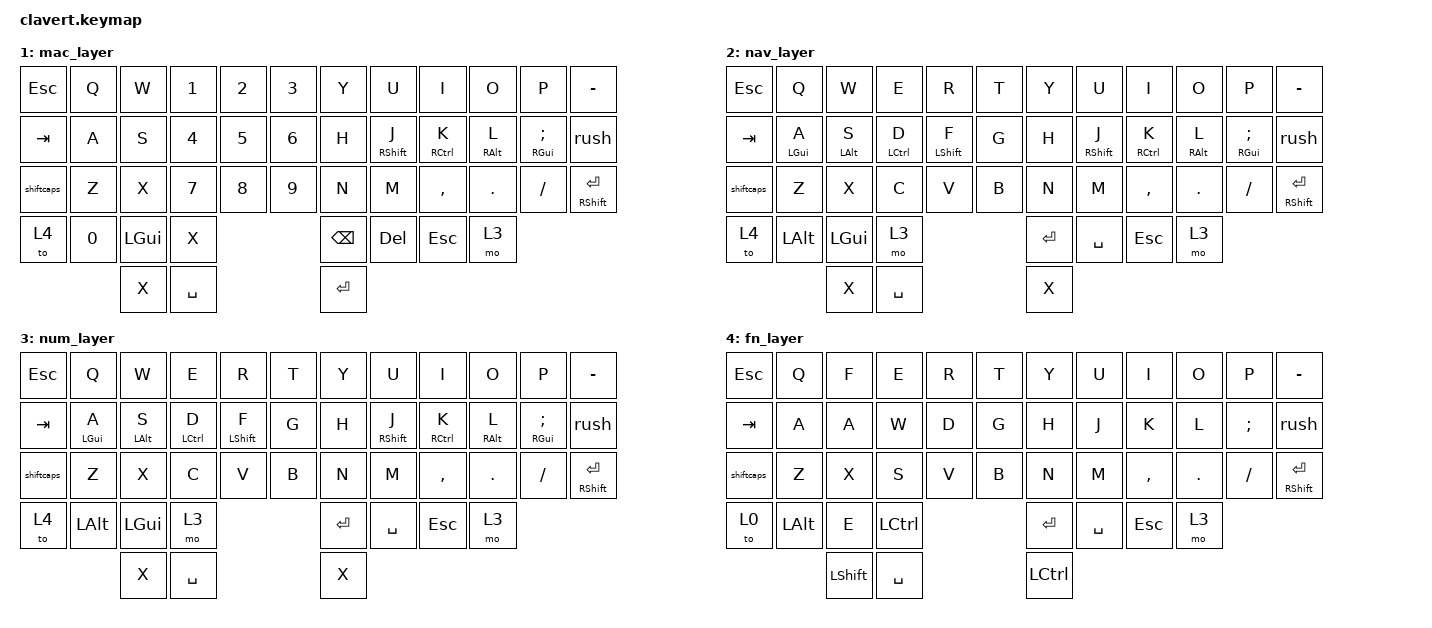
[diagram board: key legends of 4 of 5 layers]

  /*
  * Copyright (c) 2020 The ZMK Contributors
  *
  * SPDX-License-Identifier: MIT
  */

  #include <behaviors.dtsi>
  #include <dt-bindings/zmk/keys.h>
  #include <dt-bindings/zmk/bt.h>
  #include <dt-bindings/zmk/ext_power.h>
  #include <dt-bindings/zmk/pointing.h>
  #include <input/processors.dtsi>
  #include <zephyr/dt-bindings/input/input-event-codes.h>


  &sk {
    release-after-ms = <200>;
    quick-release;
    /delete-property/ ignore-modifiers;
  };
 / {
    behaviors {
      
        rush: rush {
            compatible = "zmk,behavior-tap-dance";
            label = "RUSH";
            #binding-cells = <0>;
            bindings = <&kp SQT>, <&kp LEFT_BRACKET>;
        };

        rusm: rusm {
            compatible = "zmk,behavior-tap-dance";
            label = "RUSM";
            #binding-cells = <0>;
            bindings = <&kp M>, <&kp RIGHT_BRACKET>;
        };

        shiftcaps: shiftcaps {
            compatible = "zmk,behavior-tap-dance";
            label = "SHIFTCAPS";
            #binding-cells = <0>;
            bindings = <&kp LEFT_SHIFT>, <&kp CAPS>;
        };
           
       
    };
 
    keymap {
      compatible = "zmk,keymap";
        default_layer {

          bindings = <
                                           
   &kp ESC    &kp Q           &kp W           &kp E        &kp R             &kp T           &kp Y    &kp U              &kp I        &kp O            &kp P                    &kp MINUS
   &kp TAB       &mt LEFT_GUI A  &mt LEFT_ALT S  &mt LCTRL D  &mt LEFT_SHIFT F  &kp G        &kp H    &mt RIGHT_SHIFT J  &mt RCTRL K  &mt RIGHT_ALT L  &mt RIGHT_GUI SEMICOLON  &rush
   &shiftcaps &kp Z           &kp X           &kp C        &kp V             &kp B           &kp N    &kp M              &kp COMMA    &kp DOT          &kp FSLH                 &mt RSHFT RET
   &to 4      &kp LALT        &kp LGUI        &mo 2                                          &kp BACKSPACE  &kp DEL          &kp ESC      &mo 3  
                              &mo 1           &kp SPACE                                      &kp RET &kp RET
          >;

         
        };

        mac_layer {

          bindings = <
   &kp ESC    &kp Q           &kp W           &kp 1        &kp 2             &kp 3         &kp Y    &kp U              &kp I        &kp O            &kp P                    &kp MINUS
   &kp TAB    &kp A           &kp S           &kp 4         &kp 5            &kp 6         &kp H    &mt RIGHT_SHIFT J  &mt RCTRL K  &mt RIGHT_ALT L  &mt RIGHT_GUI SEMICOLON  &rush
   &shiftcaps &kp Z           &kp X           &kp 7        &kp 8             &kp 9         &kp N    &kp M              &kp COMMA    &kp DOT          &kp FSLH                 &mt RSHFT RET
   &to 4      &kp 0        &kp LGUI           &kp X                                        &kp BACKSPACE  &kp DEL          &kp ESC      &mo 3  
                              &kp X           &kp SPACE                                    &kp RET 
>;

       
        };

        nav_layer {

          bindings = <
   &kp ESC    &kp Q           &kp W           &kp E        &kp R             &kp T       &kp Y    &kp U              &kp I        &kp O            &kp P                    &kp MINUS
   &kp TAB       &mt LEFT_GUI A  &mt LEFT_ALT S  &mt LCTRL D  &mt LEFT_SHIFT F  &kp G       &kp H    &mt RIGHT_SHIFT J  &mt RCTRL K  &mt RIGHT_ALT L  &mt RIGHT_GUI SEMICOLON  &rush
   &shiftcaps &kp Z           &kp X           &kp C        &kp V             &kp B       &kp N    &kp M              &kp COMMA    &kp DOT          &kp FSLH                 &mt RSHFT RET
   &to 4      &kp LALT        &kp LGUI        &mo 3                                      &kp RET  &kp SPACE          &kp ESC      &mo 3  
                              &kp X           &kp SPACE                                     &kp X          
          >;

        };

        num_layer {

          bindings = <
   &kp ESC    &kp Q           &kp W           &kp E        &kp R             &kp T       &kp Y    &kp U              &kp I        &kp O            &kp P                    &kp MINUS
   &kp TAB       &mt LEFT_GUI A  &mt LEFT_ALT S  &mt LCTRL D  &mt LEFT_SHIFT F  &kp G       &kp H    &mt RIGHT_SHIFT J  &mt RCTRL K  &mt RIGHT_ALT L  &mt RIGHT_GUI SEMICOLON  &rush
   &shiftcaps &kp Z           &kp X           &kp C        &kp V             &kp B       &kp N    &kp M              &kp COMMA    &kp DOT          &kp FSLH                 &mt RSHFT RET
   &to 4      &kp LALT        &kp LGUI        &mo 3                                      &kp RET  &kp SPACE          &kp ESC      &mo 3  
                              &kp X           &kp SPACE                                     &kp X           
          >;

          
        };

        fn_layer {

          bindings = <
   &kp ESC    &kp Q           &kp F           &kp E        &kp R             &kp T       &kp Y    &kp U              &kp I        &kp O            &kp P                    &kp MINUS
   &kp TAB       &kp A  &kp A  &kp W  &kp D  &kp G       &kp H    &kp J  &kp K  &kp L  &kp SEMICOLON  &rush
   &shiftcaps &kp Z           &kp X           &kp S        &kp V             &kp B       &kp N    &kp M              &kp COMMA    &kp DOT          &kp FSLH                 &mt RSHFT RET
   &to 0      &kp LALT        &kp E      &kp LCTRL                                    &kp RET  &kp SPACE          &kp ESC      &mo 3  
                              &kp LEFT_SHIFT          &kp SPACE                                      &kp LCTRL        
          >;

          
        };
    };
  };
  
